# STM32C031 register map
File version: 1.4
CPU: CM0 r0p0, little endian, MPU, FPU, 4 interrupt priority bits
Registers are 32-bit, read-write, reset 0x0 unless marked. A register's access mark holds for its fields unless they carry their own. Offsets are from the block's base; [hi:lo] are bit positions.

## FLASH — FLASH register block
Base 0x40022000
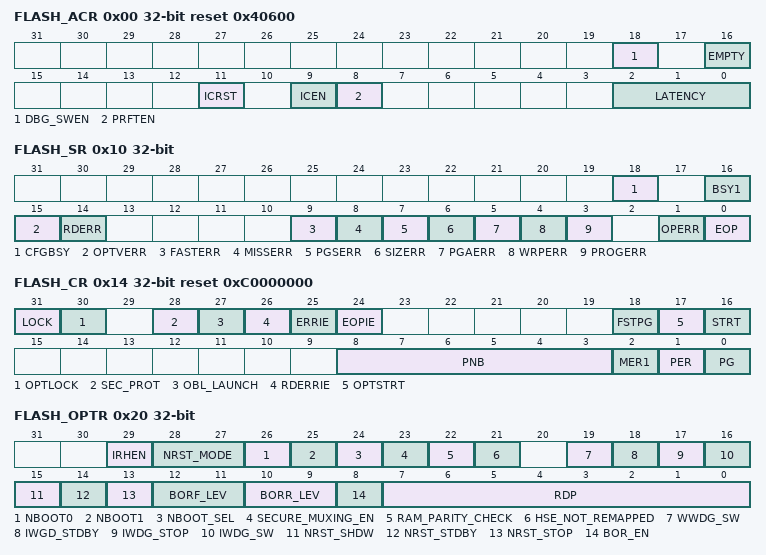
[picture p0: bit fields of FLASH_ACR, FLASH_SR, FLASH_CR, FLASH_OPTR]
0x00 FLASH_ACR reset 0x40600 (reset mask 0xFFFEFFFF) — FLASH access control register
  [18] DBG_SWEN — Debug access software enable Software may use this bit to enable/disable the debugger read access.
    0=Debugger disabled; 1=Debugger enabled
  [16] EMPTY — Main flash memory area empty This bit indicates whether the first location of the Main flash memory area was read as erased or as programmed during OBL. It is not affected by the system reset. Software may need to change this bit value after a flash memory program or erase operation. The bit can be set and reset by software.
    0=Main flash memory area programmed; 1=Main flash memory area empty
  [11] ICRST — CPU Instruction cache reset This bit can be written only when the instruction cache is disabled.
    0=CPU Instruction cache is not reset; 1=CPU Instruction cache is reset
  [9] ICEN — CPU Instruction cache enable
    0=CPU Instruction cache is disabled; 1=CPU Instruction cache is enabled
  [8] PRFTEN — CPU Prefetch enable
    0=CPU Prefetch disabled; 1=CPU Prefetch enabled
  [2:0] LATENCY — Flash memory access latency The value in this bitfield represents the number of CPU wait states when accessing the flash memory. Other: Reserved A new write into the bitfield becomes effective when it returns the same value upon read.
    0=Zero wait states; 1=One wait state
0x08 FLASH_KEYR wo — FLASH key register
  [31:0] KEY — FLASH key The following values must be written consecutively to unlock the FLASH control register (FLASH_CR), thus enabling programming/erasing operations: KEY1: 0x4567 0123 KEY2: 0xCDEF 89AB
0x0C FLASH_OPTKEYR wo — FLASH option key register
  [31:0] OPTKEY — Option byte key The following values must be written consecutively to unlock the flash memory option registers, enabling option byte programming/erasing operations: KEY1: 0x0819 2A3B KEY2: 0x4C5D 6E7F
0x10 FLASH_SR (reset mask 0xFFF0FFFF) — FLASH status register
  [18] CFGBSY ro — Programming or erase configuration busy. This flag is set and reset by hardware. For flash program operation, it is set when the first word is sent, and cleared after the second word is sent when the operation completes or ends with an error. For flash erase operation, it is set when setting the STRT bit of the FLASH_CR register and cleared when the operation completes or ends with an error. When set, a programming or erase operation is ongoing and the corresponding settings in the FLASH control register (FLASH_CR) are used (busy) and cannot be changed. Any other flash operation launch must be postponed. When cleared, the programming and erase settings in the FLASH control register (FLASH_CR) can be modified. Note: The CFGBSY bit is also set when attempting to write locked flash memory (with the first byte sent). When the CFGBSY bit is set, writing into the FLASH_CR register causes HardFault.To clear the CFGBSY bit, send a double word to the flash memory and wait until the access is finished (otherwise the CFGBSY bit remains set).
  [16] BSY1 ro — Busy This flag indicates that a flash memory operation requested by FLASH control register (FLASH_CR) is in progress. This bit is set at the beginning of the flash memory operation, and cleared when the operation finishes or when an error occurs.
  [15] OPTVERR — Option and Engineering bits loading validity error Set by hardware when the options and engineering bits read may not be the one configured by the user or production. If options and engineering bits haven't been properly loaded, OPTVERR is set again after each system reset. Option bytes that fail loading are forced to a safe value, see Section4.4.2: FLASH option byte programming. Cleared by writing 1.
  [14] RDERR — PCROP read error Set by hardware when an address to be read belongs to a read protected area of the flash memory (PCROP protection). An interrupt is generated if RDERRIE is set in FLASH_CR. Cleared by writing 1.
  [9] FASTERR — Fast programming error Set by hardware when a fast programming sequence (activated by FSTPG) is interrupted due to an error (alignment, size, write protection or data miss). The corresponding status bit (PGAERR, SIZERR, WRPERR or MISSERR) is set at the same time. Cleared by writing 1.
  [8] MISSERR — Fast programming data miss error In Fast programming mode, 16 double words (128 bytes) must be sent to flash memory successively, and the new data must be sent to the logic control before the current data is fully programmed. MISSERR is set by hardware when the new data is not present in time. Cleared by writing 1.
  [7] PGSERR — Programming sequence error Set by hardware when a write access to the flash memory is performed by the code while PG or FSTPG have not been set previously. Set also by hardware when PROGERR, SIZERR, PGAERR, WRPERR, MISSERR or FASTERR is set due to a previous programming error. Cleared by writing 1.
  [6] SIZERR — Size error Set by hardware when the size of the access is a byte or half-word during a program or a fast program sequence. Only double word programming is allowed (consequently: word access). Cleared by writing 1.
  [5] PGAERR — Programming alignment error Set by hardware when the data to program cannot be contained in the same double word (64-bit) flash memory in case of standard programming, or if there is a change of page during fast programming. Cleared by writing 1.
  [4] WRPERR — Write protection error Set by hardware when an address to be erased/programmed belongs to a write-protected part (by WRP, PCROP or RDP Level 1) of the flash memory. Cleared by writing 1.
  [3] PROGERR — Programming error Set by hardware when a double-word address to be programmed contains a value different from '0xFFFF FFFF' before programming, except if the data to write is '0x0000 0000'. Cleared by writing 1.
  [1] OPERR — Operation error Set by hardware when a flash memory operation (program / erase) completes unsuccessfully. This bit is set only if error interrupts are enabled (ERRIE=1). Cleared by writing '1'.
  [0] EOP — End of operation Set by hardware when one or more flash memory operation (programming / erase) has been completed successfully. This bit is set only if the end of operation interrupts are enabled (EOPIE=1). Cleared by writing 1.
0x14 FLASH_CR reset 0xC0000000 — FLASH control register
  [31] LOCK — FLASH_CR Lock This bit is set only. When set, the FLASH_CR register is locked. It is cleared by hardware after detecting the unlock sequence. In case of an unsuccessful unlock operation, this bit remains set until the next system reset.
  [30] OPTLOCK — Options Lock This bit is set only. When set, all bits concerning user option in FLASH_CR register and so option page are locked. This bit is cleared by hardware after detecting the unlock sequence. The LOCK bit must be cleared before doing the unlock sequence for OPTLOCK bit. In case of an unsuccessful unlock operation, this bit remains set until the next reset.
  [28] SEC_PROT — Securable memory area protection enable This bit enables the protection on securable area, provided that a non-null securable memory area size (SEC_SIZE[4:0]) is defined in option bytes. This bit is possible to set only by software and to clear only through a system reset.
    0=Disable (securable area accessible); 1=Enable (securable area not accessible)
  [27] OBL_LAUNCH — Option byte load launch When set, this bit triggers the load of option bytes into option registers. It is automatically cleared upon the completion of the load. The high state of the bit indicates pending option byte load. The bit cannot be cleared by software. It cannot be written as long as OPTLOCK is set.
  [26] RDERRIE — PCROP read error interrupt enable This bit enables the interrupt generation upon setting the RDERR flag in the FLASH_SR register.
    0=Disable; 1=Enable
  [25] ERRIE — Error interrupt enable This bit enables the interrupt generation upon setting the OPERR flag in the FLASH_SR register.
    0=Disable; 1=Enable
  [24] EOPIE — End-of-operation interrupt enable This bit enables the interrupt generation upon setting the EOP flag in the FLASH_SR register.
    0=Disable; 1=Enable
  [18] FSTPG — Fast programming enable
    0=Disable; 1=Enable
  [17] OPTSTRT — Start of modification of option bytes This bit triggers an options operation when set. This bit is set only by software, and is cleared when the BSY1 bit is cleared in FLASH_SR.
  [16] STRT — Start erase operation This bit triggers an erase operation when set. This bit is possible to set only by software and to clear only by hardware. The hardware clears it when one of BSY1 and BSY2 flags in the FLASH_SR register transits to zero.
  [8:3] PNB — Page number selection These bits select the page to erase: ... Note: Values corresponding to addresses outside the Main memory are not allowed. See Table6 and Table7.
    0=page 0; 1=page 1; 63=page 63
  [2] MER1 — Mass erase When set, this bit triggers the mass erase, that is, all user pages.
  [1] PER — Page erase enable
    0=Disable; 1=Enable
  [0] PG — Flash memory programming enable
    0=Disable; 1=Enable
0x20 FLASH_OPTR reset not defined — FLASH option register
  [29] IRHEN — Internal reset holder enable bit
    0=Internal resets are propagated as simple pulse on NRST pin; 1=Internal resets drives NRST pin low until it is seen as low level
  [28:27] NRST_MODE — NRST pin configuration
    1=Reset input only: a low level on the NRST pin generates system reset; internal RESET is not propagated to the NRST pin; 2=Standard GPIO: only internal RESET is possible; 3=Bidirectional reset: the NRST pin is configured in reset input/output (legacy) mode
  [26] NBOOT0 — nBOOT0 option bit
    0=nBOOT0=0; 1=nBOOT0=1
  [25] NBOOT1 — Boot configuration Together with the BOOT0 pin or option bit nBOOT0 (depending on nBOOT_SEL option bit configuration), this bit selects boot mode from the Main flash memory, SRAM or the System memory. Refer to Section3: Boot configuration.
  [24] NBOOT_SEL — BOOT0 signal source selection This option bit defines the source of the BOOT0 signal.
    0=BOOT0 pin (legacy mode); 1=nBOOT0 option bit
  [23] SECURE_MUXING_EN — Multiple-bonding security The bit allows enabling automatic I/O configuration to prevent conflicts on I/Os connected (bonded) onto the same pin. If the software sets one of the I/Os connected to the same pin as active by configuring the SYSCFG_CFGR3 register, enabling this bit automatically forces the other I/Os in digital input mode, regardless of their software configuration. When the bit is disabled, the SYSCFG_CFGR3 register setting is ignored, all GPIOs linked to a given pin are active and can be set in the mode specified by the corresponding GPIOx_MODER register. The user software must ensure that there is no conflict between GPIOs.
    0=Disable; 1=Enable
  [22] RAM_PARITY_CHECK — SRAM parity check control enable/disable
    0=Enable; 1=Disable
  [21] HSE_NOT_REMAPPED — HSE remapping enable/disable When cleared, the bit remaps the HSE clock source from PF0-OSC_IN/PF1-OSC_OUT pins to PC14-OSCX_IN/PC15-OSCX_OUT. Thus PC14-OSCX_IN/PC15-OSCX_OUT are shared by both LSE and HSE and the two clock sources cannot be use simultaneously. On packages with less than 48 pins, the remapping is always enabled (PF0-OSC_IN/PF1-OSC_OUT are not available), regardless of this bit. As all STM32C011xx packages have less than 48 pins, this bit is only applicable to STM32C031xx. Note: On 48 pins packages, when HSE_NOT_REMAPPED is reset, HSE cannot be used in bypass mode. Refer to product errata sheet for more details.
    0=Enable; 1=Disable
  [19] WWDG_SW — Window watchdog selection
    0=Hardware window watchdog; 1=Software window watchdog
  [18] IWGD_STDBY
  [17] IWDG_STOP — Independent watchdog counter freeze in Stop mode
    0=Independent watchdog counter is frozen in Stop mode; 1=Independent watchdog counter is running in Stop mode
  [16] IWDG_SW
  [15] NRST_SHDW
  [14] NRST_STDBY
  [13] NRST_STOP
  [12:11] BORF_LEV — BOR threshold at falling V<sub>DD</sub> supply Falling V<sub>DD</sub> crossings this threshold activates the reset signal.
    0=BOR falling level 1 with threshold around 2.0 V; 1=BOR falling level 2 with threshold around 2.2 V; 2=BOR falling level 3 with threshold around 2.5 V; 3=BOR falling level 4 with threshold around 2.8 V
  [10:9] BORR_LEV — BOR threshold at rising V<sub>DD</sub> supply Rising V<sub>DD</sub> crossings this threshold releases the reset signal.
    0=BOR rising level 1 with threshold around 2.1 V; 1=BOR rising level 2 with threshold around 2.3 V; 2=BOR rising level 3 with threshold around 2.6 V; 3=BOR rising level 4 with threshold around 2.9 V
  [8] BOR_EN — Brown out reset enable
    0=Configurable brown out reset disabled, power-on reset defined by POR/PDR levels; 1=Configurable brown out reset enabled, values of BORR_LEV and BORF_LEV taken into account
  [7:0] RDP — Read protection level Other: Level 1, memories read protection active
    170=Level 0, read protection not active; 204=Level 2, chip read protection active
0x24 FLASH_PCROP1ASR (reset mask 0xFFFFFF00) — FLASH PCROP area A start address register
  [7:0] PCROP1A_STRT — PCROP1A area start offset Contains the offset of the first subpage of the PCROP1A area. Note: The number of effective bits depends on the size of the flash memory in the device.
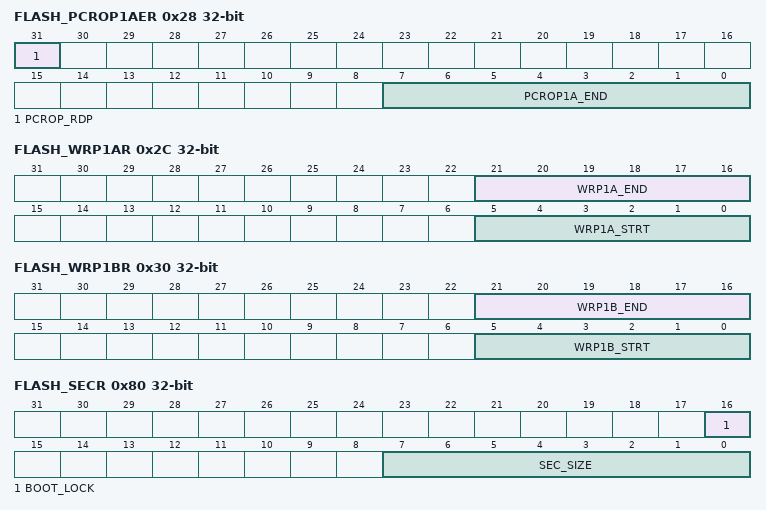
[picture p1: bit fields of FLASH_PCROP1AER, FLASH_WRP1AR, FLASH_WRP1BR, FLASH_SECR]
0x28 FLASH_PCROP1AER (reset mask 0x7FFFFF00) — FLASH PCROP area A end address register
  [31] PCROP_RDP — PCROP area erase upon RDP level regression This bit determines whether the PCROP area (and the totality of the PCROP area boundary pages) is erased by the mass erase triggered by the RDP level regression from Level 1 to Level 0: The software can only set this bit. It is automatically reset upon mass erase following the RDP regression from Level 1 to Level 0.
    0=Not erased; 1=Erased
  [7:0] PCROP1A_END — PCROP1A area end offset Contains the offset of the last subpage of the PCROP1A area. Note: The number of effective bits depends on the size of the flash memory in the device.
0x2C FLASH_WRP1AR (reset mask 0xFFC0FFC0) — FLASH WRP area A address register
  [21:16] WRP1A_END — WRP area A end offset This bitfield contains the offset of the last page of the WRP area A. Note: The number of effective bits depends on the size of the flash memory in the device.
  [5:0] WRP1A_STRT — WRP area A start offset This bitfield contains the offset of the first page of the WRP area A. Note: The number of effective bits depends on the size of the flash memory in the device.
0x30 FLASH_WRP1BR (reset mask 0xFFC0FFC0) — FLASH WRP area B address register
  [21:16] WRP1B_END — WRP area B end offset This bitfield contains the offset of the last page of the WRP area B. Note: The number of effective bits depends on the size of the flash memory in the device.
  [5:0] WRP1B_STRT — WRP area B start offset This bitfield contains the offset of the first page of the WRP area B. Note: The number of effective bits depends on the size of the flash memory in the device.
0x34 FLASH_PCROP1BSR (reset mask 0xFFFFFF00) — FLASH PCROP area B start address register
  [7:0] PCROP1B_STRT — PCROP1B area start offset Contains the offset of the first subpage of the PCROP1B area. Note: The number of effective bits depends on the size of the flash memory in the device.
0x38 FLASH_PCROP1BER (reset mask 0xFFFFFF00) — FLASH PCROP area B end address register
  [7:0] PCROP1B_END — PCROP1B area end offset Contains the offset of the last subpage of the PCROP1B area. Note: The number of effective bits depends on the size of the flash memory in the device.
0x80 FLASH_SECR (reset mask 0xFFFEFF00) — FLASH security register
  [16] BOOT_LOCK — used to force boot from user area If the bit is set in association with RDP level 1, the debug capabilities are disabled, except in the case of a bad OBL (mismatch).
    0=Boot based on the pad/option bit configuration; 1=Boot forced from Main flash memory
  [7:0] SEC_SIZE — Securable memory area size Contains the number of securable flash memory pages. Note: The number of effective bits depends on the size of the flash memory in the device.

## Notices in the file
Copyright (c) 2025 STMicroelectronics.
SPDX-License-Identifier: Apache-2.0
Licensed under the Apache License, Version 2.0 (the "License");
you may not use this file except in compliance with the License.
You may obtain a copy of the License at
http://www.apache.org/licenses/LICENSE-2.0
Unless required by applicable law or agreed to in writing, software
distributed under the License is distributed on an "AS IS" BASIS,
WITHOUT WARRANTIES OR CONDITIONS OF ANY KIND, either express or implied.
See the License for the specific language governing permissions and
limitations under the License.
